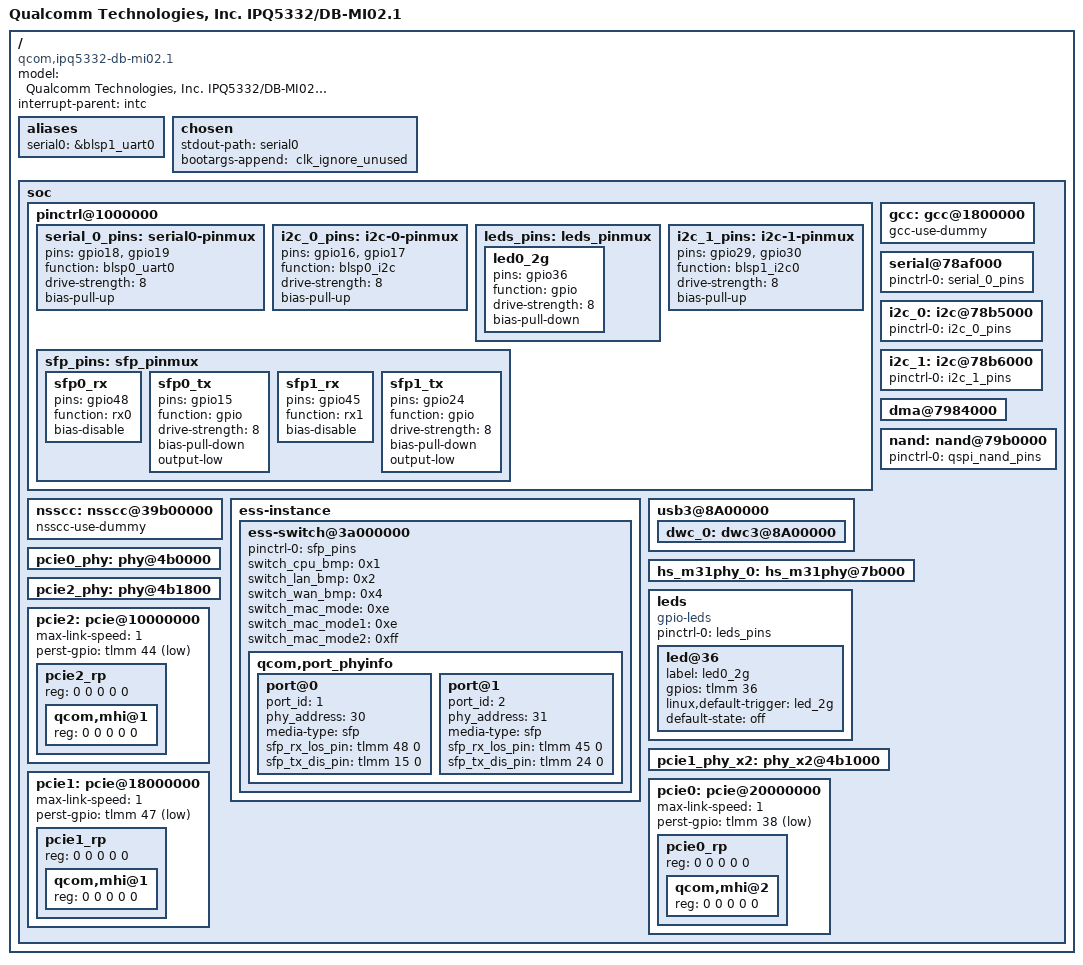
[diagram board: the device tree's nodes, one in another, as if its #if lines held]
// SPDX-License-Identifier: (GPL-2.0+ OR BSD-3-Clause)
/*
 * IPQ5332 DB-MI02.1 board device tree source
 *
 * Copyright (c) 2020-2021 The Linux Foundation. All rights reserved.
 * Copyright (c) 2022 Qualcomm Innovation Center, Inc. All rights reserved.
 */

/dts-v1/;

#include "ipq5332.dtsi"

#ifdef __IPQ_MEM_PROFILE_512_MB__
#include "ipq5332-512MB-memory.dtsi"
#else
#include "ipq5332-default-memory.dtsi"
#endif

/ {
	#address-cells = <0x2>;
	#size-cells = <0x2>;
	model = "Qualcomm Technologies, Inc. IPQ5332/DB-MI02.1";
	compatible = "qcom,ipq5332-db-mi02.1", "qcom,ipq5332";
	interrupt-parent = <&intc>;

	aliases {
		serial0 = &blsp1_uart0;
	};

	chosen {
		stdout-path = "serial0";
		bootargs-append = " clk_ignore_unused";
	};

	soc {
		pinctrl@1000000 {
			serial_0_pins: serial0-pinmux {
				pins = "gpio18", "gpio19";
				function = "blsp0_uart0";
				drive-strength = <8>;
				bias-pull-up;
			};

			i2c_0_pins: i2c-0-pinmux {
				pins = "gpio16", "gpio17";
				function = "blsp0_i2c";
				drive-strength = <8>;
				bias-pull-up;
			};

			leds_pins: leds_pinmux {
				led0_2g {
					pins = "gpio36";
					function = "gpio";
					drive-strength = <8>;
					bias-pull-down;
				};
			};

			i2c_1_pins: i2c-1-pinmux {
				pins = "gpio29", "gpio30";
				function = "blsp1_i2c0";
				drive-strength = <8>;
				bias-pull-up;
			};

			sfp_pins: sfp_pinmux {
				sfp0_rx {
					pins = "gpio48";
					function = "rx0";
					bias-disable;
				};
				sfp0_tx {
					pins = "gpio15";
					function = "gpio";
					drive-strength = <8>;
					bias-pull-down;
					output-low;
				};
				sfp1_rx {
					pins = "gpio45";
					function = "rx1";
					bias-disable;
				};
				sfp1_tx {
					pins = "gpio24";
					function = "gpio";
					drive-strength = <8>;
					bias-pull-down;
					output-low;
				};
			};
		};

		gcc: gcc@1800000 {
			gcc-use-dummy;
		};

		nsscc: nsscc@39b00000 {
			nsscc-use-dummy;
		};

		ess-instance {
			ess-switch@3a000000 {
				pinctrl-0 = <&sfp_pins>;
				pinctrl-names = "default";
				switch_cpu_bmp = <0x1>;  /* cpu port bitmap */
				switch_lan_bmp = <0x2>; /* lan port bitmap */
				switch_wan_bmp = <0x4>; /* wan port bitmap */
				switch_mac_mode = <0xe>; /* mac mode for uniphy instance0*/
				switch_mac_mode1 = <0xe>; /* mac mode for uniphy instance1*/
				switch_mac_mode2 = <0xff>; /* mac mode for uniphy instance2*/
				qcom,port_phyinfo {
					port@0 {
						port_id = <1>;
						phy_address = <30>;
						media-type = "sfp"; /* fiber mode */
						sfp_rx_los_pin = <&tlmm 48 0>;
						sfp_tx_dis_pin = <&tlmm 15 0>;

					};
					port@1 {
						port_id = <2>;
						phy_address = <31>;
						media-type = "sfp"; /* fiber mode */
						sfp_rx_los_pin = <&tlmm 45 0>;
						sfp_tx_dis_pin = <&tlmm 24 0>;
					};
				};
			};
		};

		serial@78af000 {
			pinctrl-0 = <&serial_0_pins>;
			pinctrl-names = "default";
			status = "ok";
		};

		i2c_0: i2c@78b5000 {
			pinctrl-0 = <&i2c_0_pins>;
			pinctrl-names = "default";
			status = "ok";
		};

		i2c_1: i2c@78b6000 {
			pinctrl-0 = <&i2c_1_pins>;
			pinctrl-names = "default";
			status = "ok";
		};

		dma@7984000 {
			status = "ok";
		};

		nand: nand@79b0000 {
			pinctrl-0 = <&qspi_nand_pins>;
			pinctrl-names = "default";
			status = "ok";
		};

		usb3@8A00000 {
			status = "ok";

			dwc_0: dwc3@8A00000 {
				/delete-property/ #phy-cells;
				/delete-property/ phys;
				/delete-property/ phy-names;
			};
		};

		hs_m31phy_0: hs_m31phy@7b000 {
			status = "ok";
		};

		leds {
			compatible = "gpio-leds";
			pinctrl-0 = <&leds_pins>;
			pinctrl-names = "default";
			led@36 {
				label = "led0_2g";
				gpios = <&tlmm 36 GPIO_ACTIVE_HIGH>;
				linux,default-trigger = "led_2g";
				default-state = "off";
			};
		};

		pcie0_phy: phy@4b0000 {
			status = "ok";
		};

		pcie1_phy_x2: phy_x2@4b1000 {
			status = "ok";
		};

		pcie2_phy: phy@4b1800 {
			status = "ok";
		};

		pcie2: pcie@10000000 {
			max-link-speed = <1>;
			perst-gpio = <&tlmm 44 GPIO_ACTIVE_LOW>;
			status = "ok";
			pcie2_rp {
				reg = <0 0 0 0 0>;

				qcom,mhi@1 {
					reg = <0 0 0 0 0>;
				};
			};
		};

		pcie1: pcie@18000000 {
			max-link-speed = <1>;
			perst-gpio = <&tlmm 47 GPIO_ACTIVE_LOW>;
			status = "ok";
			pcie1_rp {
				reg = <0 0 0 0 0>;

				qcom,mhi@1 {
					reg = <0 0 0 0 0>;
				};
			};
		};

		pcie0: pcie@20000000 {
			max-link-speed = <1>;
			perst-gpio = <&tlmm 38 GPIO_ACTIVE_LOW>;
			status = "ok";
			pcie0_rp {
				reg = <0 0 0 0 0>;

				qcom,mhi@2 {
					reg = <0 0 0 0 0>;
				};
			};
		};
	};
};
